# DSI1_PROTOCOL_ENGINE_L4_PER register map
Vendor: Texas Instruments
Peripheral module from a debugger description file (folder omap4430).
Registers are 32-bit, access per field, reset 0x0 unless marked. A register's access mark holds for its fields unless they carry their own. Offsets are as the file gives them; lines under a group give offsets from that group; [hi:lo] are bit positions; {n}, {i} and the like mark numbered series; 'fields as' and 'values as' point back to an identical list; <NAME> marks a mode.

## DSI1_PROTOCOL_ENGINE_L4_PER (part 1 of 2)
0x00 DSI_REVISION ro reset not defined — IP Revision
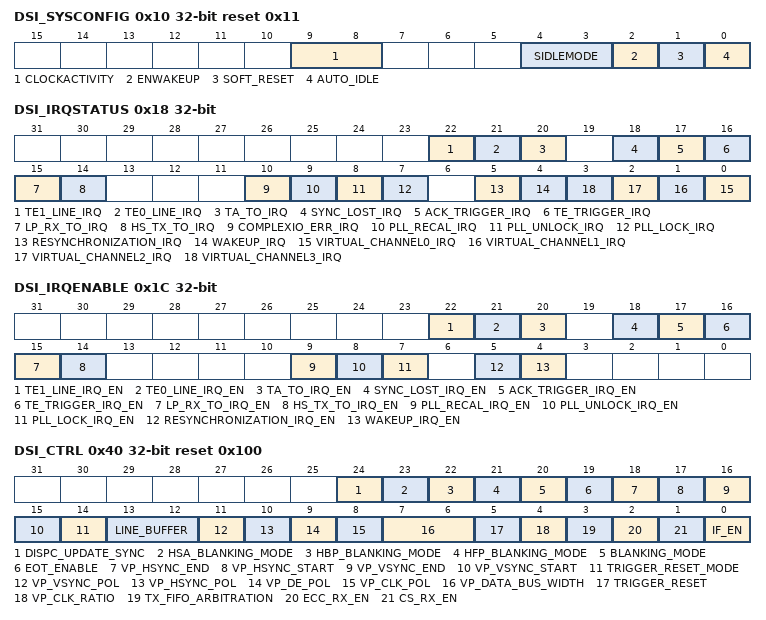
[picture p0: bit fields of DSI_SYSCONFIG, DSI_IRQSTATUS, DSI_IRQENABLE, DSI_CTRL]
0x10 DSI_SYSCONFIG reset 0x11 — SYSTEM CONFIGURATION REGISTER
  [9:8] CLOCKACTIVITY rw — Clocks activity during wake up mode period
    0=Interface and Functional clocks can be switched off; 1=Functional clocks can be switched off and Interface clocks are maintained during wake up period; 2=Interface clocks can be switched off and Functional clocks are maintained during wake up period; 3=Interface and Functional clocks are maintained during wake up period
  [4:3] SIDLEMODE rw — Slave interface power management, Idle req/ack control
    0=Force-idle. An idle request is acknowledged unconditionally; 1=No-idle. An idle request is never acknowledged; 2=Smart-idle. Acknowledgement to an idle request is given based on the internal activity of the module.
  [2] ENWAKEUP rw — Wake-up mode enable bit
    0=Wakeup is disabled; 1=Wakeup is enabled
  [1] SOFT_RESET rw — Software reset. Set the bit to 1 to trigger a module reset. The bit is automatically reset by the hardware. During reads return 0.
    0=Normal mode; 1=The module is reset
  [0] AUTO_IDLE rw — Internal interface gating strategy
    0=Interface clock is free-running; 1=Automatic Interface clock gating strategy is applied based on the interface activity
0x14 DSI_SYSSTATUS ro reset 0x1 — SYSTEM STATUS REGISTER This register provides status information about the module, excluding the interrupt status register.
  [0] RESET_DONE — Internal reset monitoring
    0=RESET_DONE_0_r (Internal module reset is on going.); 1=RESET_DONE_1_r (Reset completed.)
0x18 DSI_IRQSTATUS — INTERRUPT STATUS REGISTER - All virtual channels + Complex I/O + PLL This register associates one bit for each virtual channel in order to determine which virtual channel has generated the interrupt. The virtual channel shall be enabled for events to be generated on that virtual channel. If the virtual channel is disabled, the interrupt is not generated.
  [22] TE1_LINE_IRQ rw — The VSYNC and corresponding HSYNC pulses defined in DSI_TE_HSYNC_NUMBER for the line TE1 have been received by the DSI protocol engine and have trigger the start of the data transfer to the peripheral.
    0=READS: Event is false. WRITES: Status bit unchanged.; 1=READS: Event is true (pending). WRITES: Status bit is reset.
  [21] TE0_LINE_IRQ rw — The VSYNC and corresponding HSYNC pulses defined in DSI_TE_HSYNC_NUMBER for the line TE0 have been received by the DSI protocol engine and have trigger the start of the data transfer to the peripheral.
    values as TE1_LINE_IRQ
  [20] TA_TO_IRQ rw — Turn-around Time out.
    values as TE1_LINE_IRQ
  [18] SYNC_LOST_IRQ rw — Synchronization with Video port is lost (Video mode only)
    values as TE1_LINE_IRQ
  [17] ACK_TRIGGER_IRQ rw — Acknowledge Trigger
    values as TE1_LINE_IRQ
  [16] TE_TRIGGER_IRQ rw — Tearing Effect Trigger
    values as TE1_LINE_IRQ
  [15] LP_RX_TO_IRQ rw — Interrupt for Low Power Rx Time out
    values as TE1_LINE_IRQ
  [14] HS_TX_TO_IRQ rw — Interrupt for High Speed Tx Time out.
    values as TE1_LINE_IRQ
  [10] COMPLEXIO_ERR_IRQ ro — Error signaling from Complex I/O: status of the complex I/O errors received from the complex I/O (events are defined inDSI_COMPLEXIO_IRQSTATUS).
    0=COMPLEXIO_ERR_IRQ_0_r (READS: Event is false.); 1=COMPLEXIO_ERR_IRQ_1_r (READS: Event is true (pending).)
  [9] PLL_RECAL_IRQ rw — PLL recal event (assertion of DSIRecal signal from the DSI PLL Control module)
    values as TE1_LINE_IRQ
  [8] PLL_UNLOCK_IRQ rw — PLL un-clock event (de-assertion of DSILock signal from the DSI PLL Control module)
    values as TE1_LINE_IRQ
  [7] PLL_LOCK_IRQ rw — PLL clock event (assertion of DSILock signal from the DSI PLL Control module)
    values as TE1_LINE_IRQ
  [5] RESYNCHRONIZATION_IRQ rw — Video mode resynchronization indicates to the software users that the video port works but the configuration of the timings for the display controller (DISPC) and for DSI Protocol engine may need to be modified to avoid the resynchronization to occur.
    values as TE1_LINE_IRQ
  [4] WAKEUP_IRQ rw — Wakeup
    values as TE1_LINE_IRQ
  [n] VIRTUAL_CHANNEL{n}_IRQ ro (n=0..3) — Virtual channel {n}
    0=VIRTUAL_CHANNEL{n}_IRQ_0_r (READS: Event is false.); 1=VIRTUAL_CHANNEL{n}_IRQ_1_r (READS: Event is true (pending).)
0x1C DSI_IRQENABLE — INTERRUPT ENABLE REGISTER - This register associates one bit for each virtual channel in order to enable/disable each virtual channel individually.
  [all] fields
    0=Event is masked; 1=Event generates an interrupt when it occurs
  [22] TE1_LINE_IRQ_EN rw — The VSYNC and corresponding HSYNC pulses defined in DSI_TE_HSYNC_NUMBER for the line TE1 have been received by the DSI protocol engine and have trigger the start of the data transfer to the peripheral.
  [21] TE0_LINE_IRQ_EN rw — The VSYNC and corresponding HSYNC pulses defined in DSI_TE_HSYNC_NUMBER for the line TE0 have been received by the DSI protocol engine and have trigger the start of the data transfer to the peripheral.
  [20] TA_TO_IRQ_EN rw — Turn-around Time out.
  [18] SYNC_LOST_IRQ_EN rw — Synchronization with Video port is lost (Video mode only)
  [17] ACK_TRIGGER_IRQ_EN rw — Acknowledge trigger
  [16] TE_TRIGGER_IRQ_EN rw — Tearing Effect trigger
  [15] LP_RX_TO_IRQ_EN rw — Interrupt for Low Power Rx Time out.
  [14] HS_TX_TO_IRQ_EN rw — Interrupt for High Speed Tx Time out.
  [9] PLL_RECAL_IRQ_EN rw — PLL recal event (assertion of DSIRecal signal from the DSI PLL Control module)
  [8] PLL_UNLOCK_IRQ_EN rw — PLL un-clock event (de-assertion of DSILock signal from the DSI PLL Control module)
  [7] PLL_LOCK_IRQ_EN rw — PLL clock event (assertion of DSILock signal from the DSI PLL Control module)
  [5] RESYNCHRONIZATION_IRQ_EN rw — Video mode resynchronization
  [4] WAKEUP_IRQ_EN rw — Wakeup
0x40 DSI_CTRL reset 0x100 — GLOBAL CONTROL REGISTER This register controls the DSI Protocol Engine module. This register shall not be modified dynamically (except IF_EN bit fields).
  [24] DISPC_UPDATE_SYNC rw — Determines if the Dispc_Update_Sync signal from the display controller is used.
    0=Dispc_Update_Sync signal is not used; 1=Dispc_Update_Sync signal is used
  [23] HSA_BLANKING_MODE rw — Blanking mode
    0=Packets in TX FIFO are sent during HSA blanking period of video mode or LPS is used; 1=LONG BLANKING PACKETS only are used during HSA blanking period of video mode
  [22] HBP_BLANKING_MODE rw — Blanking mode
    0=Packets in TX FIFO are sent during HBP blanking period of video mode or LPS is used; 1=LONG BLANKING PACKETS only are used during HBP blanking period of video mode
  [21] HFP_BLANKING_MODE rw — Blanking mode
    0=Packets in TX FIFO are sent during HFP blanking period of video mode or LPS is used; 1=LONG BLANKING PACKETS only are used during HFP blanking period of video mode
  [20] BLANKING_MODE rw
    0=LPS is used during blanking periods of video mode (except HSA, HBP, HFP defined in HSA_BLANKING_MODE, HBP_BLANKING_MODE AND HFP_BLANKING_MODE respectively) when there is no command mode data in TX FIFO ready to be sent. So blanking periods can be different during the frame depending on the TX FIFO.; 1=LONG BLANKING PACKETS are used during blanking periods of video mode (except HSA, HBP, HFP defined in HSA_BLANKING_MODE, HBP_BLANKING_MODE AND HFP_BLANKING_MODE respectively) regardless of the packets present in the TX FIFO ready to be sent
  [19] EOT_ENABLE rw — Enable EOT packets at the end of HS transmission.
    0=No EOT packets; 1=EOT packet is sent at all HS to LP transitions
  [18] VP_HSYNC_END rw — HSYNC end pulse.
    0=Disabled. No HSYNC END short packet is generated.; 1=Enabled. While the HSYNC END pulse is detected, the associated short packet HSYNC END is generated.
  [17] VP_HSYNC_START rw — HSYNC start pulse.
    0=Disabled. No HSYNC START short packet is generated.; 1=Enabled. While the HSYNC start pulse is detected, the associated short packet HSYNC START is generated.
  [16] VP_VSYNC_END rw — VSYNC end pulse.
    0=Disabled. No VSYNC END short packet is generated.; 1=Enabled. While the VSYNC END pulse is detected, the associated short packet VSYNC END is generated.
  [15] VP_VSYNC_START rw — VSYNC start pulse.
    0=Disabled. No VSYNC START short packet is generated.; 1=Enabled. While the VSYNC START pulse is detected, the associated short packet VSYNC START is generated.
  [14] TRIGGER_RESET_MODE rw — Selection of the trigger reset mode
    0=Synchronized: the mode is only valid if there is virtual channel using the video mode and it is active. The principal is to wait for the current video frame to be transferred on the link. Any data received after the VSYNC are ignored.; 1=Immediate: all pending requests in TX FIFO are taken into account for transfer scheduling, the RX FIFO is ignored, and the data from video port are ignored as soon as possible. Only the current transfer on DSI link and already scheduled ones are transmitted. All the other transfers are discarded.
  [13:12] LINE_BUFFER rw — Number of line buffers to be used while receiving data on the video port. The valid values are from 0 toDSI_GNQ[17:16] VP1_NB_LINE_BUFFER.
    0=No line buffer; 1=1 line buffer; 2=2 line buffers
  [11] VP_VSYNC_POL rw — VP vertical synchronization signal polarity
    0=VSYNC signal on the video port is active low; 1=VSYNC signal on the video port is active high
  [10] VP_HSYNC_POL rw — VP horizontal synchronization signal polarity
    0=HSYNC signal on the video port is active low; 1=HSYNC signal on the video port is active high
  [9] VP_DE_POL rw — VP data enable signal polarity
    0=DE signal on the video port is active low; 1=DE signal on the video port is active high
  [8] VP_CLK_POL rw — VP pixel clock polarity
    0=The DSI Protocol Engine module captures the data on the VP on the pixel clock falling edge. The module connected to the VP shall drive the data on the pixel clock rising edge.; 1=The DSI Protocol Engine module captures the data on the VP on the pixel clock raising edge. The module connected to the VP shall drive the data on the pixel clock falling edge.
  [7:6] VP_DATA_BUS_WIDTH rw — Defines the size of the video port data bus
    0=16-bits data width (LSB of the 24-bit video port data bus); 1=18-bits data width (LSB of the 24-bit video port data bus); 2=24-bits data width (LSB of the 24-bit video port data bus)
  [5] TRIGGER_RESET rw — Send the reset trigger to the peripheral.
    0=READS: Reset trigger generation is completed. It is reset by hardware when it is completed. WRITES: Cancellation of the request for Reset trigger generation (maybe too late since it is already on going); 1=READS: Generation of the reset trigger has been requested by user (could be on going but not completed yet). WRITES: Request for Reset trigger to be sent to the peripheral.
  [4] VP_CLK_RATIO rw — The field indicates the clock ratio between VP_CLK and VP_PCLK. The clock VP_PCLK is generated from VP_CLK. It is divided down. The information is only used when the video port is used to provide data in command mode. In the case of video mode, it is not used.
    0=The clock VP_PCLK is the clock VP_CLK divided by 2. The duty cycle of VP_PCLK is 50/50.; 1=The clock VP_PCLK is the clock VP_CLK divided by 3 or more. The duty cycle of VP_PCLK is not 50/50 for odd ratio numbers (3,5,7,...).
  [3] TX_FIFO_ARBITRATION rw — Defines the arbitration scheme for granting the virtual channel pending ready requests in the TX FIFO
    0=Round-Robin Scheme is used; 1=Sequential Scheme is used
  [2] ECC_RX_EN rw — Enables the Error Correction Code check for the received header (short and long packets for all virtual channel ids).
    0=Disabled; 1=Enabled
  [1] CS_RX_EN rw — Enables the checksum check for the received payload (long packet only for all virtual channel ids).
    0=Disabled; 1=Enabled
  [0] IF_EN rw — Enables the module. When the module is disabled the signals from the complex I/O are gated (no updates of the interrupt status register). It is not possible to change the bit fields in the register DSI_CTRL except IF_EN when it is enabled. All the other registers can be changed except the ones that require DSI_VC_CTRL_i[0] VC_EN to be equal to 0 to be modified.
    0=The interface is disabled. If one of the virtual channel uses the video mode with the video port to receive the data, the DSI protocol engines is disabled when the next VSYNC is received and all the data in the FIFO for the other virtual channels in command mode are sent to the peripherals (if BTA_EN is enabled, the DSI protocol needs to wait for the response and BTA from the peripheral before disabling all the internal logic since an acknowledge is requested).; 1=The interface is enabled immediately, the data acquisition on the video port starts on the next VSYNC (video mode) or first data received in the Slave port FIFO (command mode)
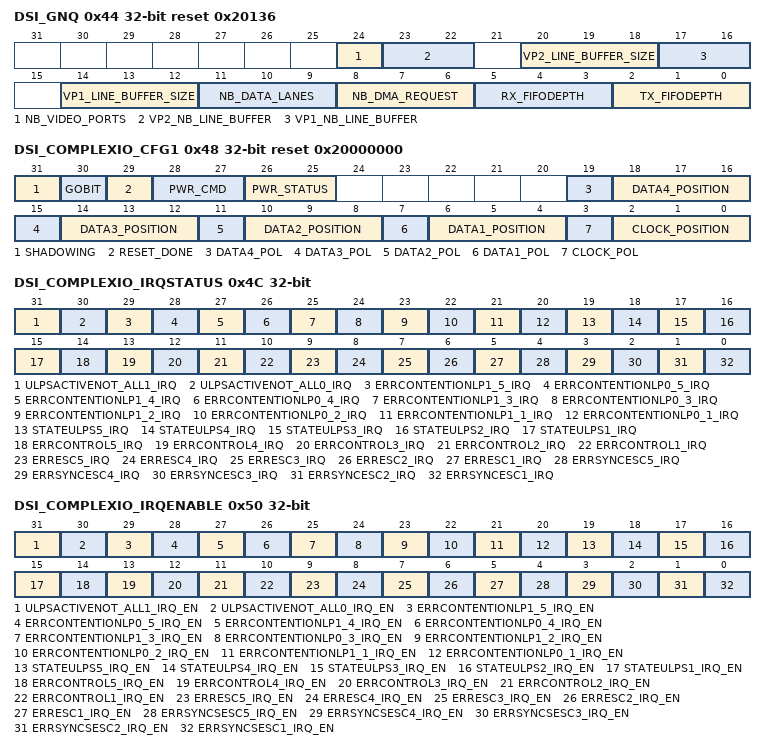
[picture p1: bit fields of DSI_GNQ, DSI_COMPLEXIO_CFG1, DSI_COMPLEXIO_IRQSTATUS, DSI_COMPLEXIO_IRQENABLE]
0x44 DSI_GNQ ro reset 0x20136 (reset mask 0xFF2381FF) — GENERIC PARAMETER REGISTER This register provide a way to read the generic parameters used in the design.
  [24] NB_VIDEO_PORTS — Number of video ports
    0=NB_VIDEO_PORTS_0_r (Video port 1 only is present); 1=NB_VIDEO_PORTS_1_r (Video port 1 and video port 2 are present)
  [23:22] VP2_NB_LINE_BUFFER — Determines the number of video buffer lines associated to video port 2.
    0=VP2_NB_LINE_BUFFER_0_r (No line buffer); 1=VP2_NB_LINE_BUFFER_1_r (1 line buffer of the size defined in LINE_BUFFER_SIZE); 2=VP2_NB_LINE_BUFFER_2_r (2 line buffers of the size defined in LINE_BUFFER_SIZE)
  [20:18] VP2_LINE_BUFFER_SIZE — Determines the video line buffer size associated to video port 2 .
    1=VP2_LINE_BUFFER_SIZE_1_r (512x24-bits, 682x18-bits, 768x16bits (memory of 384x32-bits)); 2=VP2_LINE_BUFFER_SIZE_2_r (682x24-bits, 910x18-bits, 1024x16bits (memory of 512x32-bits)); 3=VP2_LINE_BUFFER_SIZE_3_r (853x24-bits, 1137x18-bits, 1280x16bits (memory of 640x32-bits)); 4=VP2_LINE_BUFFER_SIZE_4_r (1024x24-bits, 1365x18-bits, 1536x16bits (memory of 768x32-bits)); 5=VP2_LINE_BUFFER_SIZE_5_r (1194x24-bits, 1592x18-bits, 1792x16bits (memory of 896x32-bits)); 6=VP2_LINE_BUFFER_SIZE_6_r (1365x24-bits, 1820x18-bits, 2048x16bits (memory of 1024x32-bits))
  [17:16] VP1_NB_LINE_BUFFER — Determines the number of video buffer lines associated to video port 1.
    0=VP1_NB_LINE_BUFFER_0_r (No line buffer); 1=VP1_NB_LINE_BUFFER_1_r (1 line buffer of the size defined in LINE_BUFFER_SIZE); 2=VP1_NB_LINE_BUFFER_2_r (2 line buffers of the size defined in LINE_BUFFER_SIZE)
  [14:12] VP1_LINE_BUFFER_SIZE — Determines the video line buffer size associated to video port 1 .
    1=VP1_LINE_BUFFER_SIZE_1_r (512x24-bits, 682x18-bits, 768x16bits (memory of 384x32-bits)); 2=VP1_LINE_BUFFER_SIZE_2_r (682x24-bits, 910x18-bits, 1024x16bits (memory of 512x32-bits)); 3=VP1_LINE_BUFFER_SIZE_3_r (853x24-bits, 1137x18-bits, 1280x16bits (memory of 640x32-bits)); 4=VP1_LINE_BUFFER_SIZE_4_r (1024x24-bits, 1365x18-bits, 1536x16bits (memory of 768x32-bits)); 5=VP1_LINE_BUFFER_SIZE_5_r (1194x24-bits, 1592x18-bits, 1792x16bits (memory of 896x32-bits)); 6=VP1_LINE_BUFFER_SIZE_6_r (1365x24-bits, 1820x18-bits, 2048x16bits (memory of 1024x32-bits))
  [11:9] NB_DATA_LANES — Determines the number of data lanes supported by the DSI protocol engine .
    1=NB_DATA_LANES_1_r (1 Data lane); 2=NB_DATA_LANES_2_r (2 Data lanes); 3=NB_DATA_LANES_3_r (3 Data lanes); 4=NB_DATA_LANES_4_r (4 Data lanes)
  [8:6] NB_DMA_REQUEST — Determines the number of DMA_REQ signals.
    0=NB_DMA_REQUEST_0_r (No DMA request); 1=NB_DMA_REQUEST_1_r (1 DMA request); 2=NB_DMA_REQUEST_2_r (2 DMA requests); 3=NB_DMA_REQUEST_3_r (3 DMA requests); 4=NB_DMA_REQUEST_4_r (4 DMA requests)
  [5:3] RX_FIFODEPTH — Determines the data RX FIFO depth (32-bit words) on the slave port.
    4=RX_FIFODEPTH_4_r (32x 33 bits); 5=RX_FIFODEPTH_5_r (64x 33 bits); 6=RX_FIFODEPTH_6_r (128 x 33 bits); 7=RX_FIFODEPTH_7_r (256 x 33 bits)
  [2:0] TX_FIFODEPTH — Determines the data TX FIFO depth (33-bit words) on the slave port.
    4=TX_FIFODEPTH_4_r (32x 33 bits); 5=TX_FIFODEPTH_5_r (64x 33 bits); 6=TX_FIFODEPTH_6_r (128 x 33 bits); 7=TX_FIFODEPTH_7_r (256 x 33 bits)
0x48 DSI_COMPLEXIO_CFG1 reset 0x20000000 — COMPLEXIO CONFIGURATION REGISTER for the complex I/O This register contains the lane configuration for the order and position of the lanes (clock and data) and the polarity order for the control of the PHY differential signals in addition to the control bit for the power FSM.
  [31] SHADOWING rw — Shadowing configuration.
    0=Disabled. The writes to the through registers is done like the other SCP registers.; 1=Enabled. The writes to the through registers is done only when the GOBIT is set and when the signal DISPCUpdataSync from the display controller module is active.
  [30] GOBIT rw — Allows the synchronized update of the shadow registers when the signal DISPCUpdateSync is active.
    0=Resets the GOBIT. The hardware has finished the update of the shadow SCP registers. The bit is reset by Hardware. The software can reset the bit in case the user decides to abort it. There is no guarantee that the software reset is done before the transfer of the values to the complex IO.; 1=Set the GOBIT. Only when the transfer of the new values for the three first registers is completed (3, 2, 1, or 0 transfers are performed based on the number of registers to update), the GOBIT is reset. The DISPCUpdateSync signal is used to synchronize the update. The bit shall be set only when it is in reset state.
  [29] RESET_DONE ro — Internal reset monitoring of the power domain using the TXBYTECLKHS clock from the complex I/O
    values as DSI_SYSSTATUS.RESET_DONE
  [28:27] PWR_CMD rw — Command for power control of the complex I/O
    0=Command to change to OFF state; 1=Command to change to ON state; 2=Command to change to ULTRALOW-POWER state
  [26:25] PWR_STATUS ro — Status of the power control of the complex I/O
    0=PWR_STATUS_0_r (Complex I/O in OFF state); 1=PWR_STATUS_1_r (Complex I/O in ON state); 2=PWR_STATUS_2_r (Complex I/O in ULTRALOW-POWER state)
  [19] DATA4_POL rw — +/- differential pin order of DATA lane 4. Applicable only to DS1. For DSI2 this bit field is RESERVED.
    0=+/- pin order (DSI.DX=+ and DSi.DY=-); 1=-/+ pin order (DSI.DX=- and DSi.DY=+)
  [18:16] DATA4_POSITION rw — Position and order of the DATA lane 4. Applicable only to DS1. For DSI2 this bit field is RESERVED.
    0=Not used/connected; {v}=Data lane 4 is at the position {v} (lane {v}) (v=1..5)
  [15] DATA3_POL rw — +/- differential pin order of DATA lane 3. Applicable only to DS1. For DSI2 this bit field is RESERVED.
    values as DATA4_POL
  [14:12] DATA3_POSITION rw — Position and order of the DATA lane 3. Applicable only to DS1. For DSI2 this bit field is RESERVED.
    0=Not used/connected; {v}=Data lane 3 is at the position {v} (lane {v}) (v=1..5)
  [11] DATA2_POL rw — +/- differential pin order of DATA lane 2.
    values as DATA4_POL
  [10:8] DATA2_POSITION rw — Position and order of the DATA lane 2.
    0=Not used/connected; {v}=Data lane 2 is at the position {v} (lane {v}) (v=1..5)
  [7] DATA1_POL rw — +/- pin differential pin order of DATA lane 1
    values as DATA4_POL
  [6:4] DATA1_POSITION rw — Position and order of the DATA lane 1. The data lane 1 is always present.
    0=Not used/connected; {v}=Data lane 1 is at the position {v} (lane {v}) (v=1..5)
  [3] CLOCK_POL rw — +/- differential pin order of CLOCK lane.
    values as DATA4_POL
  [2:0] CLOCK_POSITION rw — Position and order of the CLOCK lane. 0, 5, 6 and 7 are reserved. The clock lane is always present but cannot be at the position 5 even if the COMPLEX I/O consists of 5 lanes.
    0=Not used/connected; {v}=Clock lane is at the position {v} (lane {v}) (v=1..4)
0x4C DSI_COMPLEXIO_IRQSTATUS rw — INTERRUPT STATUS REGISTER - All errors from complex I/O
  [all] fields
    values as DSI_IRQSTATUS.TE1_LINE_IRQ
  [31] ULPSACTIVENOT_ALL1_IRQ — All the ULPSActiveNOT signals corresponding to the lanes with TXULPSExit being high are high.
  [30] ULPSACTIVENOT_ALL0_IRQ — All signals ULPSActiveNOT are 0
  [29] ERRCONTENTIONLP1_5_IRQ — Contention LP1 error for lane 5 Applicable only to DS1. For DSI2 this bit field is RESERVED.
  [28] ERRCONTENTIONLP0_5_IRQ — Contention LP0 error for lane 5 Applicable only to DS1. For DSI2 this bit field is RESERVED.
  [27] ERRCONTENTIONLP1_4_IRQ — Contention LP1 error for lane 4 Applicable only to DS1. For DSI2 this bit field is RESERVED.
  [26] ERRCONTENTIONLP0_4_IRQ — Contention LP0 error for lane 4 Applicable only to DS1. For DSI2 this bit field is RESERVED.
  [25] ERRCONTENTIONLP1_3_IRQ — Contention LP1 error for lane 3
  [24] ERRCONTENTIONLP0_3_IRQ — Contention LP0 error for lane 3
  [23] ERRCONTENTIONLP1_2_IRQ — Contention LP1 error for lane 2
  [22] ERRCONTENTIONLP0_2_IRQ — Contention LP0 error for lane 2
  [21] ERRCONTENTIONLP1_1_IRQ — Contention LP1 error for lane 1
  [20] ERRCONTENTIONLP0_1_IRQ — Contention LP0 error for lane 1
  [19] STATEULPS5_IRQ — lane 5 in ULTRALOW-POWER State Applicable only to DS1. For DSI2 this bit field is RESERVED.
  [18] STATEULPS4_IRQ — lane 4 in ultralow-power mode Applicable only to DS1. For DSI2 this bit field is RESERVED.
  [17] STATEULPS3_IRQ — lane 3 in ULTRALOW-POWER state
  [16] STATEULPS2_IRQ — lane 2 in ULTRALOW-POWER state
  [15] STATEULPS1_IRQ — lane 1 in ULTRALOW-POWER state
  [14] ERRCONTROL5_IRQ — Control error for lane 5 Applicable only to DS1. For DSI2 this bit field is RESERVED.
  [13] ERRCONTROL4_IRQ — Control error for lane 4 Applicable only to DS1. For DSI2 this bit field is RESERVED.
  [12] ERRCONTROL3_IRQ — Control error for lane 3
  [11] ERRCONTROL2_IRQ — Control error for lane 2
  [10] ERRCONTROL1_IRQ — Control error for lane 1
  [9] ERRESC5_IRQ — Escape entry error for lane 5 Applicable only to DS1. For DSI2 this bit field is RESERVED.
  [8] ERRESC4_IRQ — Escape entry error for lane 4 Applicable only to DS1. For DSI2 this bit field is RESERVED.
  [7] ERRESC3_IRQ — Escape entry error for lane 3
  [6] ERRESC2_IRQ — Escape entry error for lane 2
  [5] ERRESC1_IRQ — Escape entry error for lane 1
  [4] ERRSYNCESC5_IRQ — Low power Data transmission synchronization error for lane 5 Applicable only to DS1. For DSI2 this bit field is RESERVED.
  [3] ERRSYNCESC4_IRQ — Low power Data transmission synchronization error for lane 4 Applicable only to DS1. For DSI2 this bit field is RESERVED.
  [2] ERRSYNCESC3_IRQ — Low power Data transmission synchronization error for lane 3
  [1] ERRSYNCESC2_IRQ — Low power Data transmission synchronization error for lane 2
  [0] ERRSYNCESC1_IRQ — Low power Data transmission synchronization error for lane 1
0x50 DSI_COMPLEXIO_IRQENABLE rw — INTERRUPT ENABLE REGISTER - All errors from complex I/O
  [all] fields
    values as the fields of DSI_IRQENABLE
  [31] ULPSACTIVENOT_ALL1_IRQ_EN — All the ULPSActiveNOT signals corresponding to the lanes with TXULPSExit being high are high.
  [30] ULPSACTIVENOT_ALL0_IRQ_EN — All signals ULPSActiveNOT are 0
  [29] ERRCONTENTIONLP1_5_IRQ_EN — Contention LP1 error for lane 5 Applicable only to DS1. For DSI2 this bit field is RESERVED.
  [28] ERRCONTENTIONLP0_5_IRQ_EN — Contention LP0 error for lane 5 Applicable only to DS1. For DSI2 this bit field is RESERVED.
  [27] ERRCONTENTIONLP1_4_IRQ_EN — Contention LP1 error for lane 4 Applicable only to DS1. For DSI2 this bit field is RESERVED.
  [26] ERRCONTENTIONLP0_4_IRQ_EN — Contention LP0 error for lane 4 Applicable only to DS1. For DSI2 this bit field is RESERVED.
  [25] ERRCONTENTIONLP1_3_IRQ_EN — Contention LP1 error for lane 3
  [24] ERRCONTENTIONLP0_3_IRQ_EN — Contention LP0 error for lane 3
  [23] ERRCONTENTIONLP1_2_IRQ_EN — Contention LP1 error for lane 2
  [22] ERRCONTENTIONLP0_2_IRQ_EN — Contention LP0 error for lane 2
  [21] ERRCONTENTIONLP1_1_IRQ_EN — Contention LP1 error for lane 1
  [20] ERRCONTENTIONLP0_1_IRQ_EN — Contention LP0 error for lane 1
  [19] STATEULPS5_IRQ_EN — lane 5 in ULTRALOW-POWER state Applicable only to DS1. For DSI2 this bit field is RESERVED.
  [18] STATEULPS4_IRQ_EN — lane 4 in ULTRALOW-POWER state Applicable only to DS1. For DSI2 this bit field is RESERVED.
  [17] STATEULPS3_IRQ_EN — lane 3 in ULTRALOW-POWER state
  [16] STATEULPS2_IRQ_EN — lane 2 in ULTRALOW-POWER state
  [15] STATEULPS1_IRQ_EN — lane 1 in ULTRALOW-POWER state
  [14] ERRCONTROL5_IRQ_EN — Control error for lane 5 Applicable only to DS1. For DSI2 this bit field is RESERVED.
  [13] ERRCONTROL4_IRQ_EN — Control error for lane 4 Applicable only to DS1. For DSI2 this bit field is RESERVED.
  [12] ERRCONTROL3_IRQ_EN — Control error for lane 3
  [11] ERRCONTROL2_IRQ_EN — Control error for lane 2
  [10] ERRCONTROL1_IRQ_EN — Control error for lane 1
  [9] ERRESC5_IRQ_EN — Escape entry error for lane 5 Applicable only to DS1. For DSI2 this bit field is RESERVED.
  [8] ERRESC4_IRQ_EN — Escape entry error for lane 4 Applicable only to DS1. For DSI2 this bit field is RESERVED.
  [7] ERRESC3_IRQ_EN — Escape entry error for lane 3
  [6] ERRESC2_IRQ_EN — Escape entry error for lane 2
  [5] ERRESC1_IRQ_EN — Escape entry error for lane 1
  [4] ERRSYNCSESC5_IRQ_EN — Low power Data transmission synchronization error for lane 5 Applicable only to DS1. For DSI2 this bit field is RESERVED.
  [3] ERRSYNCSESC4_IRQ_EN — Low power Data transmission synchronization error for lane 4 Applicable only to DS1. For DSI2 this bit field is RESERVED.
  [2] ERRSYNCSESC3_IRQ_EN — Low power Data transmission synchronization error for lane 3
  [1] ERRSYNCSESC2_IRQ_EN — Low power Data transmission synchronization error for lane 2
  [0] ERRSYNCSESC1_IRQ_EN — Low power Data transmission synchronization error for lane 1
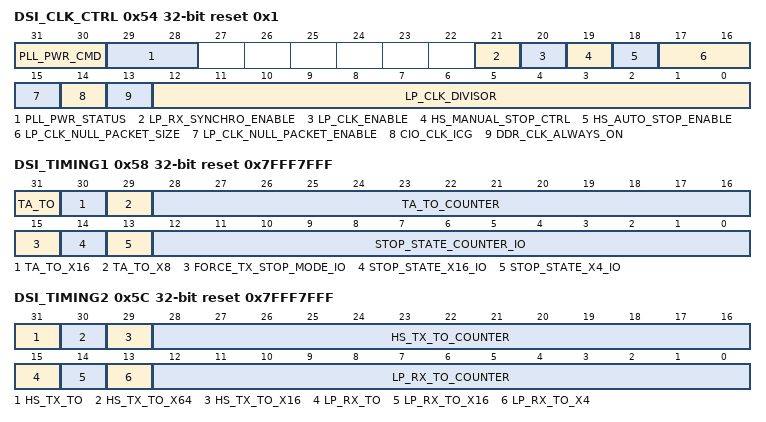
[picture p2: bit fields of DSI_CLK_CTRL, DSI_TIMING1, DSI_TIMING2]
0x54 DSI_CLK_CTRL reset 0x1 — CLOCK CONTROL This register controls the CLOCK GENERATION. The register can be modified only when IF_EN is reset.
  [31:30] PLL_PWR_CMD rw — Command for power control of the DSI PLL Control module
    0=Command to change to OFF state; 1=Command to change to ON state for PLL only (HSDIVISER is OFF); 2=Command to change to ON state for both PLL and HSDIVISER; 3=Command to change to ON state for both PLL and HSDIVISER (no clock output to the DSI complex I/O)
  [29:28] PLL_PWR_STATUS ro — Status of the power control of the DSI PLL Control module
    0=PLL_PWR_STATUS_0_r (DSI PLL Control module in OFF state); 1=PLL_PWR_STATUS_1_r (DSI PLL Control module in ON state for PLL only (HSDIVISER is OFF)); 2=PLL_PWR_STATUS_2_r (DSI PLL Control module in ON state for both PLL and HSDIVISER); 3=PLL_PWR_STATUS_3_r (DSI PLL Control module in ON state for both PLL and HSDIVISER (no clock output to the DSI complex I/O))
  [21] LP_RX_SYNCHRO_ENABLE rw — Defines if the functional is higher or lower than 30 MHz. The information is used to define synchronization to be used for RxValidEsc.
    0=The DSI functional clock is equal or slower than 30 MHz. The synchronization is falling/rising.; 1=The DSI functional clock is higher than 30 MHz. The synchronization is rising/rising.
  [20] LP_CLK_ENABLE rw — Controls the gating of the TXCLKESC clock.
    0=Disabled. The clock is not generated. The value of LP_CLK_DIVISOR is not used and does not need to be programmed.; 1=Enabled. The clock is generated. The value of LP_CLK_DIVISOR is used and needs to be programmed.
  [19] HS_MANUAL_STOP_CTRL rw — In case HS_AUTO_STOP_ENABLE=0, the bit field allows manual control of the assertion/de-assertion of the signal DSIStopClk by the user.
    0=DSIStopClk de-assertion unconditionally; 1=DSIStopClk assertion unconditionally
  [18] HS_AUTO_STOP_ENABLE rw — Enables the automatic assertion/de-assertion of DSIStopClk signal.
    0=Auto mode disabled; 1=Auto mode enabled
  [17:16] LP_CLK_NULL_PACKET_SIZE rw — Indicates the size of LP NULL Packets to be sent automatically when after the last LP packet transfer. It is used by the receiver to drain its internal pipeline. The valid values are from 0 to 3 bytes for the payload size.
  [15] LP_CLK_NULL_PACKET_ENABLE rw — Enables the generation of NULL packet in low speed.
    0=Disabled. The NULL packet is not sent in LP mode after the last LP packet.; 1=Enabled. The NULL packet is sent in LP mode after the last LP packet.
  [14] CIO_CLK_ICG rw — Gates SCPClk clock provided to DSI_PHY and PLL-CTRL module.
    0=Disabled. SCPClk is not generated. It remains at 0.; 1=Enabled. SCPClk is generated (OCP_CLK/4)
  [13] DDR_CLK_ALWAYS_ON rw — Defines if the DDR clock is also sent when there is no HS packets sent to the peripheral (low-power mode). So TXRequest for the clock lane is not de-asserted.
    0=Disabled. The DDR clock is only provided when HS packets are sent.; 1=Enabled. The DDR clock is always sent to the peripheral regardless of the state of the data lanes (HS or LS mode).
  [12:0] LP_CLK_DIVISOR rw — Defines the ratio to be used for the generation of the low-power mode clock from DSI functional clock. The supported values are from 1 to 8191(the value 0 is invalid). The output frequency shall be in the range between 20 MHz and 32 kHz.
0x58 DSI_TIMING1 rw reset 0x7FFF7FFF — TIMING1 REGISTER This register controls the DSI Protocol Engine module timers. Any bit field can be modified while [0] IF_EN is set to '1'. It is used to indicate the number of DSI1_CLK and DSI2_CLK functional clocks cycles for the timers FORCE_TX_STOP_TIMER and TA_TO_TIMER
  [31] TA_TO — Enables the turn-around timer
    0=Turn-around counter is disabled; 1=Turn-around counter is enabled (required to receive TA interrupt in case the turn-around procedure is not successful)
  [30] TA_TO_X16 — Multiplication factor for the number of DSI_CLK functional clocks cycles defined in TA_TO_COUNTER bit field
    0=The number of DSI_CLK functional clock cycles defined in TA_TO_COUNTER is multiplied by 1x; 1=The number of DSI_CLK functional clock cycles defined in TA_TO_COUNTER is multiplied by 16x
  [29] TA_TO_X8 — Multiplication factor for the number of DSI_CLK functional clock cycles defined in TA_TO_COUNTER bit field
    0=The number of DSI_CLK functional clock cycles defined in TA_TO_COUNTER is multiplied by 1x; 1=The number of DSI_CLK functional clock cycles defined in TA_TO_COUNTER is multiplied by 8x
  [28:16] TA_TO_COUNTER — Turn around counter. It indicates the number of DSI_CLK function clock to wait for the change of the Direction PPI signal according to the TurnRequest signal The value is from 0 to 8191.
  [15] FORCE_TX_STOP_MODE_IO — Control of ForceTxStopMode signal
    0=De-assertion of ForceTxStopMode. The hardware reset the bit at the end of the ForceTXStopMode assertion. The software can reset the bit in order to stop the assertion of the ForceTXStopMode signal prior to the completion of the period.; 1=Assertion of ForceTxStopMode
  [14] STOP_STATE_X16_IO — Multiplication factor for the number of DSI_CLK functional clock cycles defined in STOP_STATE_COUNTER_IO bit field
    0=The number of DSI_CLK functional clock cycles defined in STOP_STATE _COUNTER_IO is multiplied by 1x; 1=The number of DSI_CLK functional clock cycles defined in STOP_STATE _COUNTER_IO is multiplied by 16x
  [13] STOP_STATE_X4_IO — Multiplication factor for the number of DSI_CLK functional clock cycles defined in STOP_STATE_COUNTER_IO bit field
    0=The number of DSI_CLK functional clock cycles defined in STOP_STATE _COUNTER is multiplied by 1x; 1=The number of DSI_CLK functional clock cycles defined in STOP_STATE _COUNTER_IO is multiplied by 4x
  [12:0] STOP_STATE_COUNTER_IO — Stop state counter. It indicates the number of DSI_CLK function clock to assert ForceTXStopMode signal. The value is from 0 to 8191.
0x5C DSI_TIMING2 rw reset 0x7FFF7FFF — TIMING2 REGISTER This register controls the DSI Protocol Engine module timers. Any bit field can be modified while [0] IF_EN is set to '1'. It is used to indicate the number of DSI_FCLK clock cycles for the timer LP_RX_TIMER and the number of BYTE_CLK functional clock cycles for the timer HS_TX_TIMER
  [31] HS_TX_TO — Enables the HS TX timer.
    0=Time-out counter is disabled; 1=Time-out counter is enabled (required to receive TA interrupt in case the turn-around procedure is not successful)
  [30] HS_TX_TO_X64 — Multiplication factor for the number of BYTE_CLK functional clock cycles defined in HS_TX_COUNTER bit field. BYTE_CLK is a high speed transmit byte clock signal generated by the DSI_PHY.
    0=The number of BYTE_CLK functional clock cycles defined in HS_TX_TO_COUNTER is multiplied by 1x; 1=The number of BYTE_CLK functional clock cycles defined in HS_TX_TO_COUNTER is multiplied by 64x
  [29] HS_TX_TO_X16 — Multiplication factor for the number of BYTE_CLK functional clock cycles defined in HS_TX_COUNTER bit
    0=The number of BYTE_CLK functional clock cycles defined in HS_TX_TO_COUNTER is multiplied by 1x; 1=The number of BYTE_CLK functional clock cycles defined in HS_TX_TO_COUNTER is multiplied by 16x
  [28:16] HS_TX_TO_COUNTER — HS_TX_TIMER counter. It indicates the number of BYTE_CLK function clock for the HS TX timer. The value is from 0 to 8191.
  [15] LP_RX_TO — Enables the LP RX timer.
    values as DSI_TIMING1.TA_TO
  [14] LP_RX_TO_X16 — Multiplication factor for the number of DSI_FCLK clock cycles defined in LP_RX_COUNTER bit field
    0=The number of DSI_FCLK clock cycles defined in LP_RX_TO_COUNTER is multiplied by 1x; 1=The number of DSI_FCLK clock cycles defined in LP_RX_TO_COUNTER is multiplied by 16x
  [13] LP_RX_TO_X4 — Multiplication factor for the number of DSI_FCLK clock cycles defined in LP_RX_COUNTER bit
    0=The number of DSI_FCLK clock cycles defined in LP_RX_TO_COUNTER is multiplied by 1x; 1=The number of DSI_FCLK clock cycles defined in LP_RX_TO_COUNTER is multiplied by 4x
  [12:0] LP_RX_TO_COUNTER — LP_RX_TIMER counter. It indicates the number of DSI_FCLK clock for the LP RX timer. The value is from 0 to 8191.
